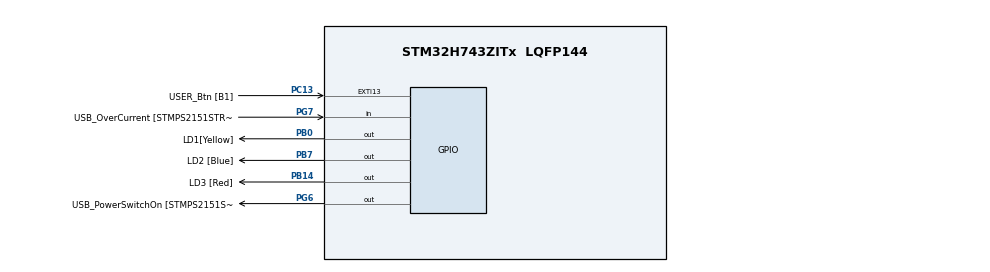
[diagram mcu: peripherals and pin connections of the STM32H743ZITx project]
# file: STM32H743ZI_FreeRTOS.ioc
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FREERTOS.Tasks01=defaultTask,0,128,StartDefaultTask,Default,NULL
Mcu.Family=STM32H7
Mcu.Name=STM32H743ZITx
Mcu.Package=LQFP144
NVIC.PriorityGroup=NVIC_PRIORITYGROUP_4
NVIC.TIM1_UP_IRQn=true\:0\:0\:false\:false\:true\:false\:false
NVIC.TimeBase=TIM1_UP_IRQn
NVIC.TimeBaseIP=TIM1
PA10.GPIO_Label=USB_ID
PA10.Signal=USB_OTG_FS_ID
PA11.GPIO_Label=USB_DM
PA11.Signal=USB_OTG_FS_DM
PA12.GPIO_Label=USB_DP
PA12.Signal=USB_OTG_FS_DP
PA13.GPIO_Label=TMS
PA13.Mode=Trace_Asynchronous_SW
PA13.Signal=SYS_JTMS-SWDIO
PA14.GPIO_Label=TCK
PA14.Mode=Trace_Asynchronous_SW
PA14.Signal=SYS_JTCK-SWCLK
PA8.GPIO_Label=USB_SOF [TP1]
PA8.Signal=USB_OTG_FS_SOF
PA9.GPIO_Label=USB_VBUS
PA9.Signal=USB_OTG_FS_VBUS
PB0.GPIO_Label=LD1[Yellow]
PB0.Signal=GPIO_Output
PB14.GPIO_Label=LD3 [Red]
PB14.Signal=GPIO_Output
PB3.GPIO_Label=SWO
PB3.Mode=Trace_Asynchronous_SW
PB3.Signal=SYS_JTDO-SWO
PB7.GPIO_Label=LD2 [Blue]
PB7.Signal=GPIO_Output
PC13.GPIO_Label=USER_Btn [B1]
PC13.Signal=GPXTI13
PC14-OSC32_IN.Signal=RCC_OSC32_IN
PC15-OSC32_OUT.Signal=RCC_OSC32_OUT
PD8.GPIO_Label=STLK_RX [STM32F103CBT6_PA3]
PD8.Signal=USART3_TX
PD9.GPIO_Label=STLK_TX [STM32F103CBT6_PA2]
PD9.Signal=USART3_RX
PG6.GPIO_Label=USB_PowerSwitchOn [STMPS2151STR_EN]
PG6.Signal=GPIO_Output
PG7.GPIO_Label=USB_OverCurrent [STMPS2151STR_FAULT]
PG7.Signal=GPIO_Input
PH0-OSC_IN.GPIO_Label=MCO
PH0-OSC_IN.Mode=HSE-External-Oscillator
PH0-OSC_IN.Signal=RCC_OSC_IN
PH1-OSC_OUT.Mode=HSE-External-Oscillator
PH1-OSC_OUT.Signal=RCC_OSC_OUT
ProjectManager.HeapSize=0x200
ProjectManager.StackSize=0x400
ProjectManager.TargetToolchain=MDK-ARM V5
RCC.48MHZClocksFreq_Value=24000000
RCC.ADCFreq_Value=129000000
RCC.AHBFreq_Value=16000000
RCC.APB1CLKDivider=RCC_HCLK_DIV2
RCC.APB1Freq_Value=100000000
RCC.APB1TimFreq_Value=16000000
RCC.APB2Freq_Value=100000000
RCC.APB2TimFreq_Value=16000000
RCC.APB3Freq_Value=100000000
RCC.APB4Freq_Value=100000000
RCC.CortexFreq_Value=400000000
RCC.D1PPRE=RCC_APB3_DIV2
RCC.D2PPRE1=RCC_APB1_DIV2
RCC.D2PPRE2=RCC_APB2_DIV2
RCC.D3PPRE=RCC_APB4_DIV2
RCC.DIVM1=4
RCC.DIVN1=50
RCC.HCLKFreq_Value=200000000
RCC.HPRE=RCC_HCLK_DIV2
RCC.HSE_VALUE=25000000
RCC.HSI_VALUE=64000000
RCC.LSE_VALUE=32768
RCC.PLLMUL=RCC_PLL_MUL9
RCC.PRESCALERUSB=RCC_USBCLKSOURCE_PLL_DIV1_5
RCC.SYSCLKFreq_VALUE=400000000
RCC.SYSCLKSource=RCC_SYSCLKSOURCE_PLLCLK
RCC.SYSCLKSourceVirtual=RCC_SYSCLKSOURCE_PLLCLK
RCC.USBFreq_Value=400000000
RCC.VCOOutputFreq_Value=192000000
VP_FREERTOS_VS_ENABLE.Mode=Enabled
VP_SYS_VS_tim1.Mode=TIM1
board=NUCLEO-H743ZI

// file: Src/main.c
/**
  ******************************************************************************
  * File Name          : main.c
  * Description        : Main program body
  ******************************************************************************
  * This notice applies to any and all portions of this file
  * that are not between comment pairs USER CODE BEGIN and
  * USER CODE END. Other portions of this file, whether
  * inserted by the user or by software development tools
  * are owned by their respective copyright owners.
  *
  * Copyright (c) 2019 STMicroelectronics International N.V.
  * All rights reserved.
  *
  * Redistribution and use in source and binary forms, with or without
  * modification, are permitted, provided that the following conditions are met:
  *
  * 1. Redistribution of source code must retain the above copyright notice,
  *    this list of conditions and the following disclaimer.
  * 2. Redistributions in binary form must reproduce the above copyright notice,
  *    this list of conditions and the following disclaimer in the documentation
  *    and/or other materials provided with the distribution.
  * 3. Neither the name of STMicroelectronics nor the names of other
  *    contributors to this software may be used to endorse or promote products
  *    derived from this software without specific written permission.
  * 4. This software, including modifications and/or derivative works of this
  *    software, must execute solely and exclusively on microcontroller or
  *    microprocessor devices manufactured by or for STMicroelectronics.
  * 5. Redistribution and use of this software other than as permitted under
  *    this license is void and will automatically terminate your rights under
  *    this license.
  *
  * THIS SOFTWARE IS PROVIDED BY STMICROELECTRONICS AND CONTRIBUTORS "AS IS"
  * AND ANY EXPRESS, IMPLIED OR STATUTORY WARRANTIES, INCLUDING, BUT NOT
  * LIMITED TO, THE IMPLIED WARRANTIES OF MERCHANTABILITY, FITNESS FOR A
  * PARTICULAR PURPOSE AND NON-INFRINGEMENT OF THIRD PARTY INTELLECTUAL PROPERTY
  * RIGHTS ARE DISCLAIMED TO THE FULLEST EXTENT PERMITTED BY LAW. IN NO EVENT
  * SHALL STMICROELECTRONICS OR CONTRIBUTORS BE LIABLE FOR ANY DIRECT, INDIRECT,
  * INCIDENTAL, SPECIAL, EXEMPLARY, OR CONSEQUENTIAL DAMAGES (INCLUDING, BUT NOT
  * LIMITED TO, PROCUREMENT OF SUBSTITUTE GOODS OR SERVICES; LOSS OF USE, DATA,
  * OR PROFITS; OR BUSINESS INTERRUPTION) HOWEVER CAUSED AND ON ANY THEORY OF
  * LIABILITY, WHETHER IN CONTRACT, STRICT LIABILITY, OR TORT (INCLUDING
  * NEGLIGENCE OR OTHERWISE) ARISING IN ANY WAY OUT OF THE USE OF THIS SOFTWARE,
  * EVEN IF ADVISED OF THE POSSIBILITY OF SUCH DAMAGE.
  *
  ******************************************************************************
  */
#include "main.h"
#include "stm32h7xx_hal.h"
#include "cmsis_os.h"

/* USER CODE BEGIN Includes */
#include "thread_led.h"
/* USER CODE END Includes */

osThreadId defaultTaskHandle;

/* USER CODE BEGIN PV */
/* Private variables ---------------------------------------------------------*/

/* USER CODE END PV */

void SystemClock_Config(void);
static void MX_GPIO_Init(void);
void StartDefaultTask(void const *argument);

/* USER CODE BEGIN PFP */
/* Private function prototypes -----------------------------------------------*/

/* USER CODE END PFP */

int main(void)
{

    /* MCU Configuration----------------------------------------------------------*/

    /* Reset of all peripherals, Initializes the Flash interface and the Systick. */
    HAL_Init();

    /* Configure the system clock */
    SystemClock_Config();

    /* Initialize all configured peripherals */
    MX_GPIO_Init();

    /* USER CODE BEGIN 2 */
    LED_INIT(); // Morgan add, 2019'4'26

    /* USER CODE END 2 */

    /* Create the thread(s) */
    /* definition and creation of defaultTask */
    osThreadDef(defaultTask, StartDefaultTask, osPriorityNormal, 0, 128);
    defaultTaskHandle = osThreadCreate(osThread(defaultTask), NULL);

    /* USER CODE BEGIN RTOS_THREADS */
    /* add threads, ... */
    TaskCreate_Led(); // Morgan add, 2019'4'26
    /* USER CODE END RTOS_THREADS */

    /* Start scheduler */
    osKernelStart();

    /* We should never get here as control is now taken by the scheduler */

    /* Infinite loop */
    while (1)
    {

    }
}

/** System Clock Configuration
*/
void SystemClock_Config(void)
{

    RCC_OscInitTypeDef RCC_OscInitStruct;
    RCC_ClkInitTypeDef RCC_ClkInitStruct;

    /**Supply configuration update enable
    */
    MODIFY_REG(PWR->CR3, PWR_CR3_SCUEN, 0);

    /**Configure the main internal regulator output voltage
    */
    __HAL_PWR_VOLTAGESCALING_CONFIG(PWR_REGULATOR_VOLTAGE_SCALE1);

    while ((PWR->D3CR & (PWR_D3CR_VOSRDY)) != PWR_D3CR_VOSRDY)
    {
    }
    /**Initializes the CPU, AHB and APB busses clocks
    */
    RCC_OscInitStruct.OscillatorType = RCC_OSCILLATORTYPE_HSI;
    RCC_OscInitStruct.HSIState = RCC_HSI_DIV1;
    RCC_OscInitStruct.HSICalibrationValue = 16;
    RCC_OscInitStruct.PLL.PLLState = RCC_PLL_ON;
    RCC_OscInitStruct.PLL.PLLSource = RCC_PLLSOURCE_HSI;
    RCC_OscInitStruct.PLL.PLLM = 4;
    RCC_OscInitStruct.PLL.PLLN = 50;
    RCC_OscInitStruct.PLL.PLLP = 2;
    RCC_OscInitStruct.PLL.PLLQ = 2;
    RCC_OscInitStruct.PLL.PLLR = 2;
    RCC_OscInitStruct.PLL.PLLRGE = RCC_PLL1VCIRANGE_3;
    RCC_OscInitStruct.PLL.PLLVCOSEL = RCC_PLL1VCOWIDE;
    RCC_OscInitStruct.PLL.PLLFRACN = 0;
    if (HAL_RCC_OscConfig(&RCC_OscInitStruct) != HAL_OK)
    {
        _Error_Handler(__FILE__, __LINE__);
    }

    /**Initializes the CPU, AHB and APB busses clocks
    */
    RCC_ClkInitStruct.ClockType = RCC_CLOCKTYPE_HCLK | RCC_CLOCKTYPE_SYSCLK | RCC_CLOCKTYPE_PCLK1 | RCC_CLOCKTYPE_PCLK2 | RCC_CLOCKTYPE_D3PCLK1 | RCC_CLOCKTYPE_D1PCLK1;
    RCC_ClkInitStruct.SYSCLKSource = RCC_SYSCLKSOURCE_PLLCLK;
    RCC_ClkInitStruct.SYSCLKDivider = RCC_SYSCLK_DIV1;
    RCC_ClkInitStruct.AHBCLKDivider = RCC_HCLK_DIV2;
    RCC_ClkInitStruct.APB3CLKDivider = RCC_APB3_DIV2;
    RCC_ClkInitStruct.APB1CLKDivider = RCC_APB1_DIV2;
    RCC_ClkInitStruct.APB2CLKDivider = RCC_APB2_DIV2;
    RCC_ClkInitStruct.APB4CLKDivider = RCC_APB4_DIV2;

    if (HAL_RCC_ClockConfig(&RCC_ClkInitStruct, FLASH_LATENCY_2) != HAL_OK)
    {
        _Error_Handler(__FILE__, __LINE__);
    }

    /**Configure the Systick interrupt time
    */
    HAL_SYSTICK_Config(SystemCoreClock / 1000);

    /**Configure the Systick
    */
    HAL_SYSTICK_CLKSourceConfig(SYSTICK_CLKSOURCE_HCLK);

    /* SysTick_IRQn interrupt configuration */
    HAL_NVIC_SetPriority(SysTick_IRQn, 15, 0);
}

/** Configure pins as
        * Analog
        * Input
        * Output
        * EVENT_OUT
        * EXTI
     PD8   ------> USART3_TX
     PD9   ------> USART3_RX
     PA8   ------> USB_OTG_FS_SOF
     PA10   ------> USB_OTG_FS_ID
     PA11   ------> USB_OTG_FS_DM
     PA12   ------> USB_OTG_FS_DP
*/
static void MX_GPIO_Init(void)
{

    GPIO_InitTypeDef GPIO_InitStruct;

    /* GPIO Ports Clock Enable */
    __HAL_RCC_GPIOC_CLK_ENABLE();
    __HAL_RCC_GPIOH_CLK_ENABLE();
    __HAL_RCC_GPIOB_CLK_ENABLE();
    __HAL_RCC_GPIOD_CLK_ENABLE();
    __HAL_RCC_GPIOG_CLK_ENABLE();
    __HAL_RCC_GPIOA_CLK_ENABLE();

    /*Configure GPIO pin : USER_Btn_Pin */
    GPIO_InitStruct.Pin = USER_Btn_Pin;
    GPIO_InitStruct.Mode = GPIO_MODE_IT_RISING;
    GPIO_InitStruct.Pull = GPIO_NOPULL;
    HAL_GPIO_Init(USER_Btn_GPIO_Port, &GPIO_InitStruct);

    /*Configure GPIO pins : LD1_Pin LD3_Pin LD2_Pin */
    GPIO_InitStruct.Pin = LD1_Pin | LD3_Pin | LD2_Pin;
    GPIO_InitStruct.Mode = GPIO_MODE_OUTPUT_PP;
    GPIO_InitStruct.Pull = GPIO_NOPULL;
    GPIO_InitStruct.Speed = GPIO_SPEED_FREQ_LOW;
    HAL_GPIO_Init(GPIOB, &GPIO_InitStruct);

    /*Configure GPIO pins : STLK_RX_Pin STLK_TX_Pin */
    GPIO_InitStruct.Pin = STLK_RX_Pin | STLK_TX_Pin;
    GPIO_InitStruct.Mode = GPIO_MODE_AF_PP;
    GPIO_InitStruct.Pull = GPIO_NOPULL;
    GPIO_InitStruct.Speed = GPIO_SPEED_FREQ_LOW;
    GPIO_InitStruct.Alternate = GPIO_AF7_USART3;
    HAL_GPIO_Init(GPIOD, &GPIO_InitStruct);

    /*Configure GPIO pin : USB_PowerSwitchOn_Pin */
    GPIO_InitStruct.Pin = USB_PowerSwitchOn_Pin;
    GPIO_InitStruct.Mode = GPIO_MODE_OUTPUT_PP;
    GPIO_InitStruct.Pull = GPIO_NOPULL;
    GPIO_InitStruct.Speed = GPIO_SPEED_FREQ_LOW;
    HAL_GPIO_Init(USB_PowerSwitchOn_GPIO_Port, &GPIO_InitStruct);

    /*Configure GPIO pin : USB_OverCurrent_Pin */
    GPIO_InitStruct.Pin = USB_OverCurrent_Pin;
    GPIO_InitStruct.Mode = GPIO_MODE_INPUT;
    GPIO_InitStruct.Pull = GPIO_NOPULL;
    HAL_GPIO_Init(USB_OverCurrent_GPIO_Port, &GPIO_InitStruct);

    /*Configure GPIO pins : USB_SOF_Pin USB_ID_Pin USB_DM_Pin USB_DP_Pin */
    GPIO_InitStruct.Pin = USB_SOF_Pin | USB_ID_Pin | USB_DM_Pin | USB_DP_Pin;
    GPIO_InitStruct.Mode = GPIO_MODE_AF_PP;
    GPIO_InitStruct.Pull = GPIO_NOPULL;
    GPIO_InitStruct.Speed = GPIO_SPEED_FREQ_LOW;
    GPIO_InitStruct.Alternate = GPIO_AF10_OTG1_FS;
    HAL_GPIO_Init(GPIOA, &GPIO_InitStruct);
}

/* StartDefaultTask function */
void StartDefaultTask(void const *argument)
{

    for (;;)
    {
        osDelay(1);
    }
}

void HAL_TIM_PeriodElapsedCallback(TIM_HandleTypeDef *htim)
{
    if (htim->Instance == TIM1)
    {
        HAL_IncTick();
    }
}

void _Error_Handler(char *file, int line)
{
    while (1)
    {
    }
}

/************************ (C) COPYRIGHT STMicroelectronics *****END OF FILE****/
